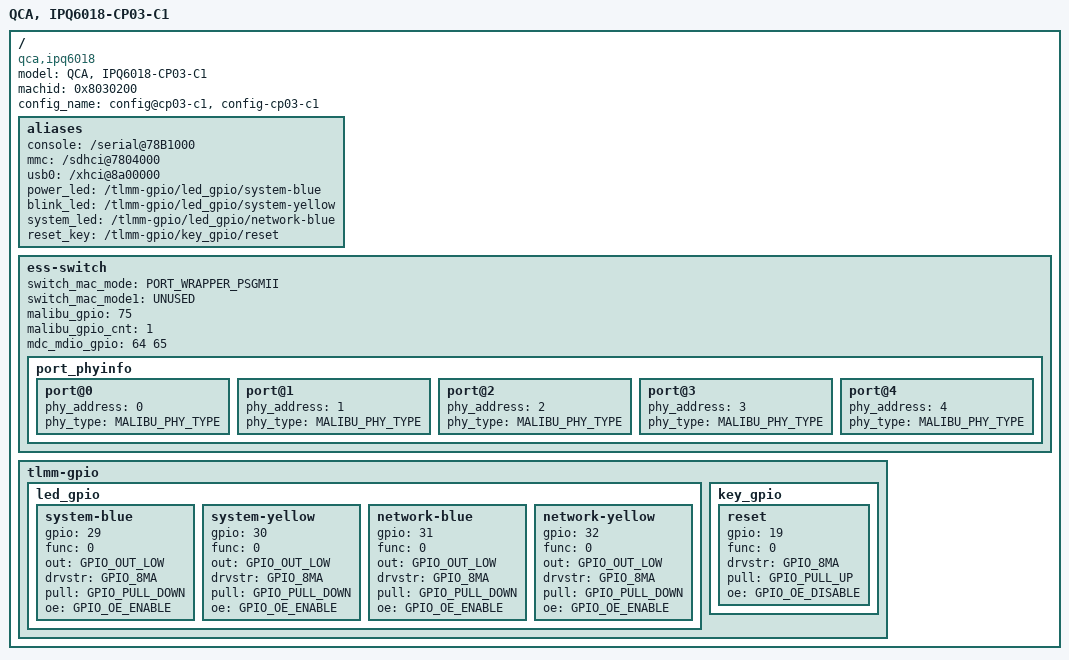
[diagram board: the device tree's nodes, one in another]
/*
 * Copyright (c) 2019, The Linux Foundation. All rights reserved.
 *
 * This program is free software; you can redistribute it and/or modify
 * it under the terms of the GNU General Public License version 2 and
 * only version 2 as published by the Free Software Foundation.
 *
 * This program is distributed in the hope that it will be useful,
 * but WITHOUT ANY WARRANTY; without even the implied warranty of
 * MERCHANTABILITY or FITNESS FOR A PARTICULAR PURPOSE.  See the
 * GNU General Public License for more details.
 */

/dts-v1/;
#include "ipq6018-soc.dtsi"
/ {
	model ="QCA, IPQ6018-CP03-C1";
	compatible = "qca,ipq6018", "qca,ipq6018-cp03-c1";
	machid = <0x8030200>;
	config_name = "config@cp03-c1", "config-cp03-c1";

	aliases {
		console = "/serial@78B1000";
		mmc = "/sdhci@7804000";
		usb0 = "/xhci@8a00000";
		power_led = "/tlmm-gpio/led_gpio/system-blue";
		blink_led = "/tlmm-gpio/led_gpio/system-yellow";
		system_led = "/tlmm-gpio/led_gpio/network-blue";
		reset_key = "/tlmm-gpio/key_gpio/reset";
	};

	ess-switch {
		switch_mac_mode = <PORT_WRAPPER_PSGMII>;
		switch_mac_mode1 = <UNUSED>;
		malibu_gpio = <75>;
		malibu_gpio_cnt = <1>;
		mdc_mdio_gpio = <64 65>;
		port_phyinfo {
			port@0 {
				phy_address = <0>;
				phy_type = <MALIBU_PHY_TYPE>;
			};
			port@1 {
				phy_address = <1>;
				phy_type = <MALIBU_PHY_TYPE>;
			};
			port@2 {
				phy_address = <2>;
				phy_type = <MALIBU_PHY_TYPE>;
			};
			port@3 {
				phy_address = <3>;
				phy_type = <MALIBU_PHY_TYPE>;
			};
			port@4 {
				phy_address = <4>;
				phy_type = <MALIBU_PHY_TYPE>;
			};
		};
	};

	tlmm-gpio {
		led_gpio {
			system-blue {
				gpio = <29>;
				func = <0>;
				out = <GPIO_OUT_LOW>;
				drvstr = <GPIO_8MA>;
				pull = <GPIO_PULL_DOWN>;
				oe = <GPIO_OE_ENABLE>;
			};
			system-yellow {
				gpio = <30>;
				func = <0>;
				out = <GPIO_OUT_LOW>;
				drvstr = <GPIO_8MA>;
				pull = <GPIO_PULL_DOWN>;
				oe = <GPIO_OE_ENABLE>;
			};
			network-blue {
				gpio = <31>;
				func = <0>;
				out = <GPIO_OUT_LOW>;
				drvstr = <GPIO_8MA>;
				pull = <GPIO_PULL_DOWN>;
				oe = <GPIO_OE_ENABLE>;
			};
			network-yellow {
				gpio = <32>;
				func = <0>;
				out = <GPIO_OUT_LOW>;
				drvstr = <GPIO_8MA>;
				pull = <GPIO_PULL_DOWN>;
				oe = <GPIO_OE_ENABLE>;
			};
		};

		key_gpio {
			reset {
				gpio = <19>;
				func = <0>;
				drvstr = <GPIO_8MA>;
				pull = <GPIO_PULL_UP>;
				oe = <GPIO_OE_DISABLE>;
			};
		};
	};
};

